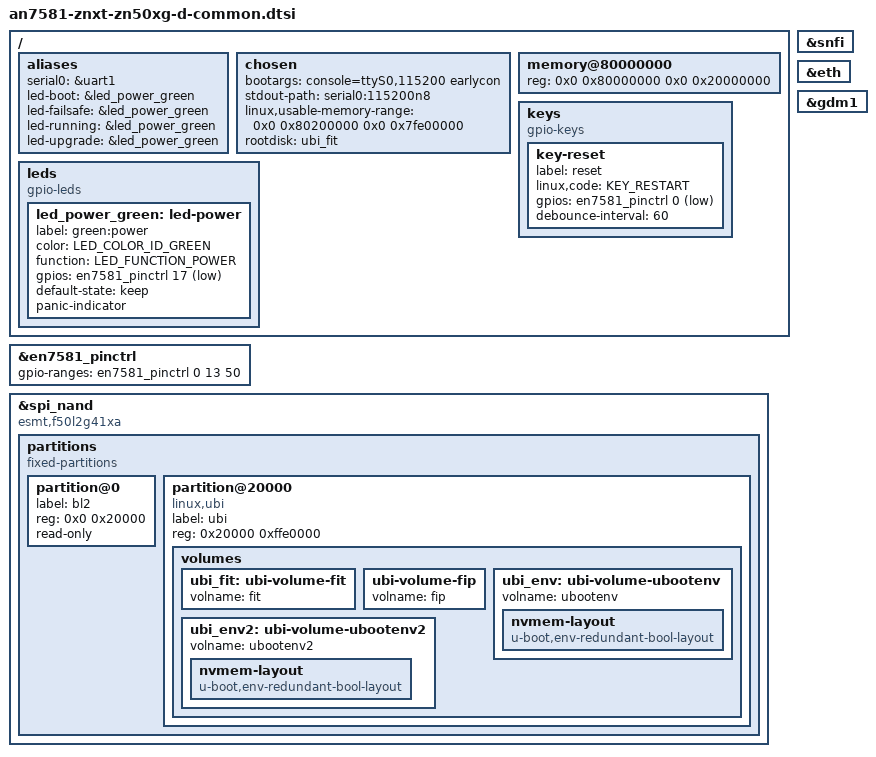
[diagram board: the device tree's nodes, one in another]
// SPDX-License-Identifier: (GPL-2.0-only OR BSD-2-Clause)

/dts-v1/;

#include <dt-bindings/gpio/gpio.h>
#include <dt-bindings/input/input.h>
#include <dt-bindings/leds/common.h>
#include "an7581.dtsi"

/*
 * First drop follows other-board/: UART, reset, power LED, SPI-NAND, gdm1.
 * Internal switch ports, USB and any 2.5G PHY are not described yet.
 *
 * F50L2G41XA is 256 MiB; BL2 takes the first 128 KiB, UBI the rest.
 */

/ {
	aliases {
		serial0 = &uart1;
		led-boot = &led_power_green;
		led-failsafe = &led_power_green;
		led-running = &led_power_green;
		led-upgrade = &led_power_green;
	};

	chosen {
		bootargs = "console=ttyS0,115200 earlycon";
		stdout-path = "serial0:115200n8";
		linux,usable-memory-range = <0x0 0x80200000 0x0 0x7fe00000>;
		rootdisk = <&ubi_fit>;
	};

	memory@80000000 {
		device_type = "memory";
		reg = <0x0 0x80000000 0x0 0x20000000>;
	};

	keys {
		compatible = "gpio-keys";

		key-reset {
			label = "reset";
			linux,code = <KEY_RESTART>;
			gpios = <&en7581_pinctrl 0 GPIO_ACTIVE_LOW>;
			debounce-interval = <60>;
		};
	};

	leds {
		compatible = "gpio-leds";

		led_power_green: led-power {
			label = "green:power";
			color = <LED_COLOR_ID_GREEN>;
			function = LED_FUNCTION_POWER;
			gpios = <&en7581_pinctrl 17 GPIO_ACTIVE_LOW>;
			default-state = "keep";
			panic-indicator;
		};
	};
};

&en7581_pinctrl {
	gpio-ranges = <&en7581_pinctrl 0 13 50>;
};

&snfi {
	status = "okay";
};

&spi_nand {
	/* ID 2c:24 covers multiple geometries; the board compatible selects F50L2G41XA. */
	compatible = "esmt,f50l2g41xa", "spi-nand";

	partitions {
		compatible = "fixed-partitions";
		#address-cells = <1>;
		#size-cells = <1>;

		partition@0 {
			label = "bl2";
			reg = <0x0 0x20000>;
			read-only;
		};

		partition@20000 {
			label = "ubi";
			reg = <0x20000 0xffe0000>;
			compatible = "linux,ubi";

			volumes {
				ubi_fit: ubi-volume-fit {
					volname = "fit";
				};

				ubi-volume-fip {
					volname = "fip";
				};

				ubi_env: ubi-volume-ubootenv {
					volname = "ubootenv";
				};

				ubi_env2: ubi-volume-ubootenv2 {
					volname = "ubootenv2";
				};
			};
		};
	};
};

&ubi_env {
	nvmem-layout {
		compatible = "u-boot,env-redundant-bool-layout";
	};
};

&ubi_env2 {
	nvmem-layout {
		compatible = "u-boot,env-redundant-bool-layout";
	};
};

&eth {
	status = "okay";
};

&gdm1 {
	status = "okay";
};
